# TC37XPD register map
Vendor: Infineon; Series: ATVMC; File version: 100
CPU: other r0p0, little endian, MPU, FPU, vendor SysTick, 4 interrupt priority bits
Registers are 32-bit, read-write, reset 0x0 unless marked. A register's access mark holds for its fields unless they carry their own. Offsets are from the block's base; [hi:lo] are bit positions; {n}, {i} and the like mark numbered series; 'fields as' and 'values as' point back to an identical list.

## STM0 — STM
Base 0xF0001000
Same registers: STM1 0xF0001100, STM2 0xF0001200
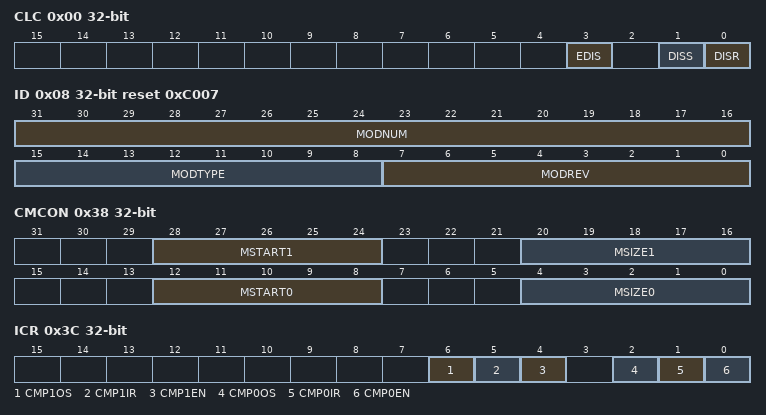
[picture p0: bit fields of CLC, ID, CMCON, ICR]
0x00 CLC access per field — Clock Control Register resetvalue={Application Reset:0x0}
  [3] EDIS rw — Sleep Mode Enable Control EDIS. Used for module sleep mode control.
  [1] DISS ro — Module Disable Status Bit DISS. Bit indicates the current status of the STM module.
  [0] DISR rw — Module Disable Request Bit DISR. Used for enable disable control of the STM module. f STM is generated by the CCU.
0x08 ID ro reset 0xC007 — Module Identification Register resetvalue={Application Reset:0x0C007}
  [31:16] MODNUM — Module Number Value MODNUM. This bit field defines the module identification number for the STM 0068 H
  [15:8] MODTYPE — Module Type MODTYPE. This bit field defines the module as a 32 bit module C0 H
  [7:0] MODREV — Module Revision Number MODREV. MODREV defines the module revision number. The value of a module revision starts with 01 H first revision . Current revision is 0x7.
0x10 TIM0 ro — Timer Register 0 resetvalue={Application Reset:0x0}
  [31:0] STM_31_0 — System Timer Bits 31 0 STM 31 0 . This bit field contains bits 31 0 of the 64 bit STM.
0x14 TIM1 ro — Timer Register 1 resetvalue={Application Reset:0x0}
  [31:0] STM_35_4 — System Timer Bits 35 4 STM 35 4 . This bit field contains bits 35 4 of the 64 bit STM.
0x18 TIM2 ro — Timer Register 2 resetvalue={Application Reset:0x0}
  [31:0] STM_39_8 — System Timer Bits 39 8 STM 39 8 . This bit field contains bits 39 8 of the 64 bit STM.
0x1C TIM3 ro — Timer Register 3 resetvalue={Application Reset:0x0}
  [31:0] STM_43_12 — System Timer Bits 43 12 STM 43 12 . This bit field contains bits 43 12 of the 64 bit STM.
0x20 TIM4 ro — Timer Register 4 resetvalue={Application Reset:0x0}
  [31:0] STM_47_16 — System Timer Bits 47 16 STM 47 16 . This bit field contains bits 47 16 of the 64 bit STM.
0x24 TIM5 ro — Timer Register 5 resetvalue={Application Reset:0x0}
  [31:0] STM_51_20 — System Timer Bits 51 20 STM 51 20 . This bit field contains bits 51 20 of the 64 bit STM.
0x28 TIM6 ro — Timer Register 6 resetvalue={Application Reset:0x0}
  [31:0] STM_63_32 — System Timer Bits 63 32 STM 63 32 . This bit field contains bits 63 32 of the 64 bit STM.
0x2C CAP ro — Timer Capture Register resetvalue={Application Reset:0x0}
  [31:0] STMCAP_63_32 — Captured System Timer Bits 63 32 STMCAP 63 32 . The capture register STMCAP always captures the STM bits 63 32 when one of the registers TIM0 to TIM6 or TIM0SV is read. This capture operation is performed in order to enable software to operate with a coherent value of all the 64 STM bits at one time stamp.This bit field contains bits 63 32 of the 64 bit STM. Reading register TIM0SV captures also the read value for register TIM6. In this way reading TIM0SV followed by CAPSV delivers the timer values for the first read request.
{0x30+4i} CMPx[{i}] (i=0..1) — Compare Register 0 resetvalue={Application Reset:0x0}
  [31:0] CMPVAL — Compare Value of Compare Register x CMPVAL. This bit field holds up to 32 bits of the compare value right adjusted .
0x38 CMCON — Compare Match Control Register resetvalue={Application Reset:0x0}
  [28:24] MSTART1 — Start Bit Location for CMP1 MSTART1. This bit field determines the lowest bit number of the 64 bit STM that is compared with the content of register CMP1 bit 0. The number of bits to be compared is defined by bit field MSIZE1. ...
  [20:16] MSIZE1 — Compare Register Size for CMP1 MSIZE1. This bit field determines the number of bits in register CMP1 starting from bit 0 that are used for the compare operation with the System Timer. ...
  [12:8] MSTART0 — Start Bit Location for CMP0 MSTART0. This bit field determines the lowest bit number of the 64 bit STM that is compared with the content of register CMP0 bit 0. The number of bits to be compared is defined by bit field MSIZE0. ...
  [4:0] MSIZE0 — Compare Register Size for CMP0 MSIZE0. This bit field determines the number of bits in register CMP0 starting from bit 0 that are used for the compare operation with the System Timer. ...
0x3C ICR access per field — Interrupt Control Register resetvalue={Application Reset:0x0}
  [6] CMP1OS rw — Compare Register CMP1 Interrupt Output Selection CMP1OS. This bit determines the interrupt output that is activated on a compare match event of compare register CMP1.
  [5] CMP1IR ro — Compare Register CMP1 Interrupt Request Flag CMP1IR. This bit indicates whether or not a compare match event of compare register CMP1 has occured. CMP1IR can be cleared by software and can be set by software too see ISCR register . After a STM reset operation CMP1IR is immediately set as a result of a compare match event with the reset values of the STM and the compare register CMP1. This flag does not gate the interrupt generation. i.e. even if this flag is not cleared compare match event interrupts are forwarded if CMPxEN is set.
  [4] CMP1EN rw — Compare Register CMP1 Interrupt Enable Control CMP1EN. This bit enables the compare match interrupt with compare register CMP1.
  [2] CMP0OS rw — Compare Register CMP0 Interrupt Output Selection CMP0OS. This bit determines the interrupt output that is activated on a compare match event of compare register CMP0.
  [1] CMP0IR ro — Compare Register CMP0 Interrupt Request Flag CMP0IR. This bit indicates whether or not a compare match event of compare register CMP0 has occured. CMP0IR can be cleared by software and can be set by software too see ISCR register . After a STM reset operation CMP0IR is immediately set as a result of a compare match event with the reset values of the STM and the compare registers CMP0. This flag does not gate the interrupt generation. i.e. even if this flag is not cleared compare match event interrupts are forwarded if CMPxEN is set.
  [0] CMP0EN rw — Compare Register CMP0 Interrupt Enable Control CMP0EN. This bit enables the compare match interrupt with compare register CMP0.
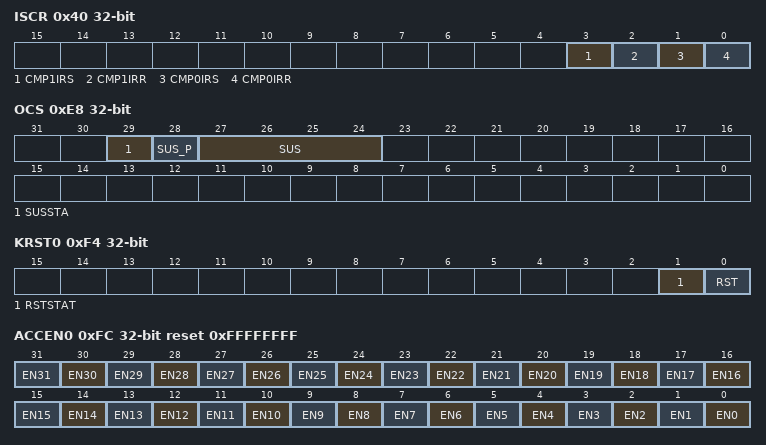
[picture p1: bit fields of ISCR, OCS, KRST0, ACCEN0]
0x40 ISCR wo — Interrupt Set Clear Register resetvalue={Application Reset:0x0}
  [3] CMP1IRS — Set Compare Register CMP1 Interrupt Flag CMP1IRS
  [2] CMP1IRR — Reset Compare Register CMP1 Interrupt Flag CMP1IRR
  [1] CMP0IRS — Set Compare Register CMP0 Interrupt Flag CMP0IRS
  [0] CMP0IRR — Reset Compare Register CMP0 Interrupt Flag CMP0IRR
0x50 TIM0SV ro — Timer Register 0 Second View resetvalue={Application Reset:0x0}
  fields as TIM0
0x54 CAPSV ro — Timer Capture Register Second View resetvalue={Application Reset:0x0}
  fields as CAP
0xE8 OCS access per field — OCDS Control and Status Register resetvalue={Debug Reset:0x0}
  [29] SUSSTA ro — Suspend State SUSSTA
  [28] SUS_P wo — SUS Write Protection SUS P. SUS is only written when SUS P is 1 otherwise unchanged. Read as 0.
  [27:24] SUS rw — OCDS Suspend Control SUS. Controls the sensitivity of STMx to the suspend signal coming from CPUx CPUxSUSOUT
0xEC KRSTCLR wo — Kernel Reset Status Clear Register resetvalue={Application Reset:0x0}
  [0] CLR — Kernel Reset Status Clear CLR. Read always as 0.
0xF0 KRST1 — Kernel Reset Register 1 resetvalue={Application Reset:0x0}
  [0] RST — Kernel Reset RST. This reset bit can be used to request for a kernel reset. The kernel reset will be executed if the reset bits of both kernel reset registers is set. The RST bit will be cleared re set to 0 after the kernel reset was executed.
0xF4 KRST0 access per field — Kernel Reset Register 0 resetvalue={Application Reset:0x0}
  [1] RSTSTAT ro — Kernel Reset Status RSTSTAT. This bit indicates wether a kernel reset was executed or not. This bit is set by the BPI FPI after the execution of a kernel reset in the same clock cycle both reset bits. This bit can be cleared by writing with 1 to the CLR bit in the related KRSTCLR register.
  [0] RST rw — Kernel Reset RST. This reset bit can be used to request for a kernel reset. The kernel reset will be executed if the reset bits of both kernel registers are set. The RST bit will be cleared re set to 0 by the BPI FPI after the kernel reset was executed.
0xFC ACCEN0 reset 0xFFFFFFFF — Access Enable Register 0 resetvalue={Application Reset:0x0FFFFFFFF}
  [n] EN{n} (n=0..31) — Access Enable for Master TAG ID 31 EN31. This bit enables write access to the module kernel addresses for transactions with the Master TAG ID n
